# MSPM0L134X register map
Vendor: Texas Instruments; File version: This preliminary header file does not have a version number - build date: 2023-02-21 16:43:37
CPU: CM0 r0p1, little endian, MPU, no FPU, 3 interrupt priority bits
Registers are 32-bit, read-write, reset 0x0 unless marked. A register's access mark holds for its fields unless they carry their own. Offsets are from the block's base; [hi:lo] are bit positions; {n}, {i} and the like mark numbered series.

## UART0 — PERIPHERALREGION
Base 0x40108000
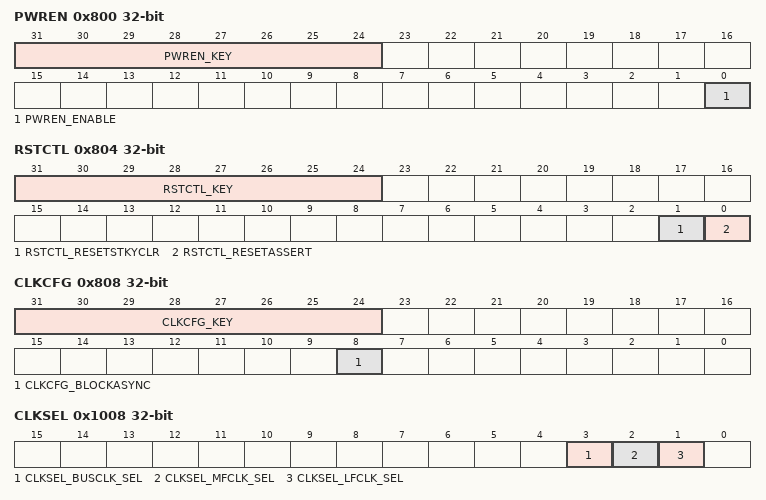
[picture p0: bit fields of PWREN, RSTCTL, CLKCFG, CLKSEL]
0x800 PWREN — Power enable
  [31:24] PWREN_KEY wo — KEY to allow Power State Change
    38=PWREN_KEY_UNLOCK_W (_TO_UNLOCK_W_)
  [0] PWREN_ENABLE — Enable the power
    0=PWREN_ENABLE_DISABLE (DISABLE); 1=PWREN_ENABLE_ENABLE (ENABLE)
0x804 RSTCTL wo — Reset Control
  [31:24] RSTCTL_KEY — Unlock key
    177=RSTCTL_KEY_UNLOCK_W (_TO_UNLOCK_W_)
  [1] RSTCTL_RESETSTKYCLR — Clear the RESETSTKY bit in the STAT register
    0=RSTCTL_RESETSTKYCLR_NOP (NOP); 1=RSTCTL_RESETSTKYCLR_CLR (CLR)
  [0] RSTCTL_RESETASSERT — Assert reset to the peripheral
    0=RSTCTL_RESETASSERT_NOP (NOP); 1=RSTCTL_RESETASSERT_ASSERT (ASSERT)
0x808 CLKCFG — Peripheral Clock Configuration Register
  [31:24] CLKCFG_KEY wo — KEY to Allow State Change -- 0xA9
    169=CLKCFG_KEY_UNLOCK (_UNLOCK_W_)
  [8] CLKCFG_BLOCKASYNC — Async Clock Request is blocked from starting SYSOSC or forcing bus clock to 32MHz
    0=CLKCFG_BLOCKASYNC_DISABLE (DISABLE); 1=CLKCFG_BLOCKASYNC_ENABLE (ENABLE)
0x814 GPRCM_STAT ro — Status Register
  [16] GPRCM_STAT_RESETSTKY — This bit indicates, if the peripheral was reset, since this bit was cleared by RESETSTKYCLR in the RSTCTL register
    0=GPRCM_STAT_RESETSTKY_NORES (NORES); 1=GPRCM_STAT_RESETSTKY_RESET (RESET)
0x1000 CLKDIV — Clock Divider
  [2:0] CLKDIV_RATIO — Selects divide ratio of module clock
    {v}=CLKDIV_RATIO_DIV_BY_{v+1} (DIV_BY_{v+1}) (v=0..7)
0x1008 CLKSEL — Clock Select for Ultra Low Power peripherals
  [3] CLKSEL_BUSCLK_SEL — Selects BUS CLK as clock source if enabled
    0=CLKSEL_BUSCLK_SEL_DISABLE (DISABLE); 1=CLKSEL_BUSCLK_SEL_ENABLE (ENABLE)
  [2] CLKSEL_MFCLK_SEL — Selects MFCLK as clock source if enabled
    0=CLKSEL_MFCLK_SEL_DISABLE (DISABLE); 1=CLKSEL_MFCLK_SEL_ENABLE (ENABLE)
  [1] CLKSEL_LFCLK_SEL — Selects LFCLK as clock source if enabled
    0=CLKSEL_LFCLK_SEL_DISABLE (DISABLE); 1=CLKSEL_LFCLK_SEL_ENABLE (ENABLE)
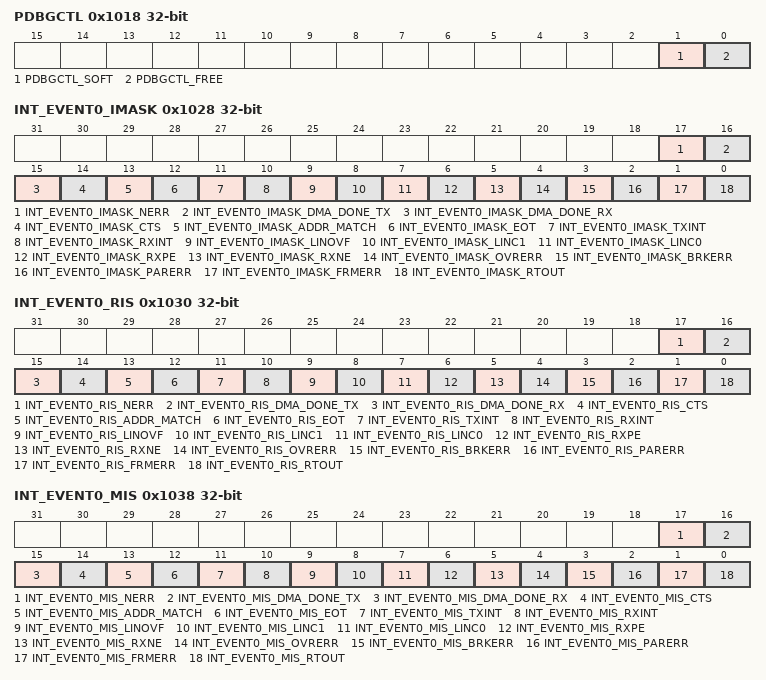
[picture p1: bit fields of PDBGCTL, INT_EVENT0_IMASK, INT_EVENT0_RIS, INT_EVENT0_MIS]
0x1018 PDBGCTL — Peripheral Debug Control
  [1] PDBGCTL_SOFT — Soft halt boundary control. This function is only available, if [FREE] is set to 'STOP'
    0=PDBGCTL_SOFT_IMMEDIATE (IMMEDIATE); 1=PDBGCTL_SOFT_DELAYED (DELAYED)
  [0] PDBGCTL_FREE — Free run control
    0=PDBGCTL_FREE_STOP (STOP); 1=PDBGCTL_FREE_RUN (RUN)
0x1020 INT_EVENT0_IIDX ro — Interrupt index
  [7:0] INT_EVENT0_IIDX_STAT — UART Module Interrupt Vector Value. This register provides the highes priority interrupt index. A read clears the corresponding interrupt flag in UARTRIS and UARTMISC. 15h-1Fh = Reserved
    0=INT_EVENT0_IIDX_STAT_NO_INTR (NO_INTR); 1=INT_EVENT0_IIDX_STAT_RTFG (RTFG); 2=INT_EVENT0_IIDX_STAT_FEFG (FEFG); 3=INT_EVENT0_IIDX_STAT_PEFG (PEFG); 4=INT_EVENT0_IIDX_STAT_BEFG (BEFG); 5=INT_EVENT0_IIDX_STAT_OEFG (OEFG); 6=INT_EVENT0_IIDX_STAT_RXNE (RXNE); 7=INT_EVENT0_IIDX_STAT_RXPE (RXPE); 8=INT_EVENT0_IIDX_STAT_LINC0 (LINC0); 9=INT_EVENT0_IIDX_STAT_LINC1 (LINC1); 10=INT_EVENT0_IIDX_STAT_LINOVF (LINOVF); 11=INT_EVENT0_IIDX_STAT_RXIFG (RXIFG); 12=INT_EVENT0_IIDX_STAT_TXIFG (TXIFG); 13=INT_EVENT0_IIDX_STAT_EOT (EOT); 14=INT_EVENT0_IIDX_STAT_MODE_9B (MODE_9B); 15=INT_EVENT0_IIDX_STAT_CTS (CTS); 16=INT_EVENT0_IIDX_STAT_DMA_DONE_RX (DMA_DONE_RX); 17=INT_EVENT0_IIDX_STAT_DMA_DONE_TX (DMA_DONE_TX); 18=INT_EVENT0_IIDX_STAT_NERR_EVT (NERR_EVT)
0x1028 INT_EVENT0_IMASK — Interrupt mask
  [17] INT_EVENT0_IMASK_NERR — Noise Error on triple voting. Asserted when the 3 samples of majority voting are not equal
    0=INT_EVENT0_IMASK_NERR_CLR (CLR); 1=INT_EVENT0_IMASK_NERR_SET (SET)
  [16] INT_EVENT0_IMASK_DMA_DONE_TX — Enable DMA Done on TX Event Channel
    0=INT_EVENT0_IMASK_DMA_DONE_TX_CLR (CLR); 1=INT_EVENT0_IMASK_DMA_DONE_TX_SET (SET)
  [15] INT_EVENT0_IMASK_DMA_DONE_RX — Enable DMA Done on RX Event Channel
    0=INT_EVENT0_IMASK_DMA_DONE_RX_CLR (CLR); 1=INT_EVENT0_IMASK_DMA_DONE_RX_SET (SET)
  [14] INT_EVENT0_IMASK_CTS — Enable UART Clear to Send Modem Interrupt. 0 = Interrupt disabled
    0=INT_EVENT0_IMASK_CTS_CLR (CLR); 1=INT_EVENT0_IMASK_CTS_SET (SET)
  [13] INT_EVENT0_IMASK_ADDR_MATCH — Enable Address Match Interrupt.
    0=INT_EVENT0_IMASK_ADDR_MATCH_CLR (CLR); 1=INT_EVENT0_IMASK_ADDR_MATCH_SET (SET)
  [12] INT_EVENT0_IMASK_EOT — Enable UART End of Transmission Interrupt Indicates that the last bit of all transmitted data and flags has left the serializer and without any further Data in the TX Fifo or Buffer.
    0=INT_EVENT0_IMASK_EOT_CLR (CLR); 1=INT_EVENT0_IMASK_EOT_SET (SET)
  [11] INT_EVENT0_IMASK_TXINT — Enable UART Transmit Interrupt.
    0=INT_EVENT0_IMASK_TXINT_CLR (CLR); 1=INT_EVENT0_IMASK_TXINT_SET (SET)
  [10] INT_EVENT0_IMASK_RXINT — Enable UART Receive Interrupt.
    0=INT_EVENT0_IMASK_RXINT_CLR (CLR); 1=INT_EVENT0_IMASK_RXINT_SET (SET)
  [9] INT_EVENT0_IMASK_LINOVF — Enable LIN Hardware Counter Overflow Interrupt.
    0=INT_EVENT0_IMASK_LINOVF_CLR (CLR); 1=INT_EVENT0_IMASK_LINOVF_SET (SET)
  [8] INT_EVENT0_IMASK_LINC1 — Enable LIN Capture 1 Interrupt.
    0=INT_EVENT0_IMASK_LINC1_CLR (CLR); 1=INT_EVENT0_IMASK_LINC1_SET (SET)
  [7] INT_EVENT0_IMASK_LINC0 — Enable LIN Capture 0 / Match Interrupt .
    0=INT_EVENT0_IMASK_LINC0_CLR (CLR); 1=INT_EVENT0_IMASK_LINC0_SET (SET)
  [6] INT_EVENT0_IMASK_RXPE — Enable Positive Edge on UARTxRXD Interrupt.
    0=INT_EVENT0_IMASK_RXPE_CLR (CLR); 1=INT_EVENT0_IMASK_RXPE_SET (SET)
  [5] INT_EVENT0_IMASK_RXNE — Enable Negative Edge on UARTxRXD Interrupt.
    0=INT_EVENT0_IMASK_RXNE_CLR (CLR); 1=INT_EVENT0_IMASK_RXNE_SET (SET)
  [4] INT_EVENT0_IMASK_OVRERR — Enable UART Receive Overrun Error Interrupt.
    0=INT_EVENT0_IMASK_OVRERR_CLR (CLR); 1=INT_EVENT0_IMASK_OVRERR_SET (SET)
  [3] INT_EVENT0_IMASK_BRKERR — Enable UART Break Error Interrupt.
    0=INT_EVENT0_IMASK_BRKERR_CLR (CLR); 1=INT_EVENT0_IMASK_BRKERR_SET (SET)
  [2] INT_EVENT0_IMASK_PARERR — Enable UART Parity Error Interrupt.
    0=INT_EVENT0_IMASK_PARERR_CLR (CLR); 1=INT_EVENT0_IMASK_PARERR_SET (SET)
  [1] INT_EVENT0_IMASK_FRMERR — Enable UART Framing Error Interrupt.
    0=INT_EVENT0_IMASK_FRMERR_CLR (CLR); 1=INT_EVENT0_IMASK_FRMERR_SET (SET)
  [0] INT_EVENT0_IMASK_RTOUT — Enable UARTOUT Receive Time-Out Interrupt.
    0=INT_EVENT0_IMASK_RTOUT_CLR (CLR); 1=INT_EVENT0_IMASK_RTOUT_SET (SET)
0x1030 INT_EVENT0_RIS ro — Raw interrupt status
  [17] INT_EVENT0_RIS_NERR — Noise Error on triple voting. Asserted when the 3 samples of majority voting are not equal
    0=INT_EVENT0_RIS_NERR_CLR (CLR); 1=INT_EVENT0_RIS_NERR_SET (SET)
  [16] INT_EVENT0_RIS_DMA_DONE_TX — DMA Done on TX Event Channel
    0=INT_EVENT0_RIS_DMA_DONE_TX_CLR (CLR); 1=INT_EVENT0_RIS_DMA_DONE_TX_SET (SET)
  [15] INT_EVENT0_RIS_DMA_DONE_RX — DMA Done on RX Event Channel
    0=INT_EVENT0_RIS_DMA_DONE_RX_CLR (CLR); 1=INT_EVENT0_RIS_DMA_DONE_RX_SET (SET)
  [14] INT_EVENT0_RIS_CTS — UART Clear to Send Modem Interrupt. 0 = Interrupt disabled
    0=INT_EVENT0_RIS_CTS_CLR (CLR); 1=INT_EVENT0_RIS_CTS_SET (SET)
  [13] INT_EVENT0_RIS_ADDR_MATCH — Address Match Interrupt.
    0=INT_EVENT0_RIS_ADDR_MATCH_CLR (CLR); 1=INT_EVENT0_RIS_ADDR_MATCH_SET (SET)
  [12] INT_EVENT0_RIS_EOT — UART End of Transmission Interrupt Indicates that the last bit of all transmitted data and flags has left the serializer and without any further Data in the TX Fifo or Buffer.
    0=INT_EVENT0_RIS_EOT_CLR (CLR); 1=INT_EVENT0_RIS_EOT_SET (SET)
  [11] INT_EVENT0_RIS_TXINT — UART Transmit Interrupt.
    0=INT_EVENT0_RIS_TXINT_CLR (CLR); 1=INT_EVENT0_RIS_TXINT_SET (SET)
  [10] INT_EVENT0_RIS_RXINT — UART Receive Interrupt.
    0=INT_EVENT0_RIS_RXINT_CLR (CLR); 1=INT_EVENT0_RIS_RXINT_SET (SET)
  [9] INT_EVENT0_RIS_LINOVF — LIN Hardware Counter Overflow Interrupt.
    0=INT_EVENT0_RIS_LINOVF_CLR (CLR); 1=INT_EVENT0_RIS_LINOVF_SET (SET)
  [8] INT_EVENT0_RIS_LINC1 — LIN Capture 1 Interrupt.
    0=INT_EVENT0_RIS_LINC1_CLR (CLR); 1=INT_EVENT0_RIS_LINC1_SET (SET)
  [7] INT_EVENT0_RIS_LINC0 — LIN Capture 0 / Match Interrupt .
    0=INT_EVENT0_RIS_LINC0_CLR (CLR); 1=INT_EVENT0_RIS_LINC0_SET (SET)
  [6] INT_EVENT0_RIS_RXPE — Positive Edge on UARTxRXD Interrupt.
    0=INT_EVENT0_RIS_RXPE_CLR (CLR); 1=INT_EVENT0_RIS_RXPE_SET (SET)
  [5] INT_EVENT0_RIS_RXNE — Negative Edge on UARTxRXD Interrupt.
    0=INT_EVENT0_RIS_RXNE_CLR (CLR); 1=INT_EVENT0_RIS_RXNE_SET (SET)
  [4] INT_EVENT0_RIS_OVRERR — UART Receive Overrun Error Interrupt.
    0=INT_EVENT0_RIS_OVRERR_CLR (CLR); 1=INT_EVENT0_RIS_OVRERR_SET (SET)
  [3] INT_EVENT0_RIS_BRKERR — UART Break Error Interrupt.
    0=INT_EVENT0_RIS_BRKERR_CLR (CLR); 1=INT_EVENT0_RIS_BRKERR_SET (SET)
  [2] INT_EVENT0_RIS_PARERR — UART Parity Error Interrupt.
    0=INT_EVENT0_RIS_PARERR_CLR (CLR); 1=INT_EVENT0_RIS_PARERR_SET (SET)
  [1] INT_EVENT0_RIS_FRMERR — UART Framing Error Interrupt.
    0=INT_EVENT0_RIS_FRMERR_CLR (CLR); 1=INT_EVENT0_RIS_FRMERR_SET (SET)
  [0] INT_EVENT0_RIS_RTOUT — UARTOUT Receive Time-Out Interrupt.
    0=INT_EVENT0_RIS_RTOUT_CLR (CLR); 1=INT_EVENT0_RIS_RTOUT_SET (SET)
0x1038 INT_EVENT0_MIS ro — Masked interrupt status
  [17] INT_EVENT0_MIS_NERR — Noise Error on triple voting. Asserted when the 3 samples of majority voting are not equal
    0=INT_EVENT0_MIS_NERR_CLR (CLR); 1=INT_EVENT0_MIS_NERR_SET (SET)
  [16] INT_EVENT0_MIS_DMA_DONE_TX — Masked DMA Done on TX Event Channel
    0=INT_EVENT0_MIS_DMA_DONE_TX_CLR (CLR); 1=INT_EVENT0_MIS_DMA_DONE_TX_SET (SET)
  [15] INT_EVENT0_MIS_DMA_DONE_RX — Masked DMA Done on RX Event Channel
    0=INT_EVENT0_MIS_DMA_DONE_RX_CLR (CLR); 1=INT_EVENT0_MIS_DMA_DONE_RX_SET (SET)
  [14] INT_EVENT0_MIS_CTS — Masked UART Clear to Send Modem Interrupt. 0 = Interrupt disabled
    0=INT_EVENT0_MIS_CTS_CLR (CLR); 1=INT_EVENT0_MIS_CTS_SET (SET)
  [13] INT_EVENT0_MIS_ADDR_MATCH — Masked Address Match Interrupt.
    0=INT_EVENT0_MIS_ADDR_MATCH_CLR (CLR); 1=INT_EVENT0_MIS_ADDR_MATCH_SET (SET)
  [12] INT_EVENT0_MIS_EOT — UART End of Transmission Interrupt Indicates that the last bit of all transmitted data and flags has left the serializer and without any further Data in the TX Fifo or Buffer.
    0=INT_EVENT0_MIS_EOT_CLR (CLR); 1=INT_EVENT0_MIS_EOT_SET (SET)
  [11] INT_EVENT0_MIS_TXINT — Masked UART Transmit Interrupt.
    0=INT_EVENT0_MIS_TXINT_CLR (CLR); 1=INT_EVENT0_MIS_TXINT_SET (SET)
  [10] INT_EVENT0_MIS_RXINT — Masked UART Receive Interrupt.
    0=INT_EVENT0_MIS_RXINT_CLR (CLR); 1=INT_EVENT0_MIS_RXINT_SET (SET)
  [9] INT_EVENT0_MIS_LINOVF — Masked LIN Hardware Counter Overflow Interrupt.
    0=INT_EVENT0_MIS_LINOVF_CLR (CLR); 1=INT_EVENT0_MIS_LINOVF_SET (SET)
  [8] INT_EVENT0_MIS_LINC1 — Masked LIN Capture 1 Interrupt.
    0=INT_EVENT0_MIS_LINC1_CLR (CLR); 1=INT_EVENT0_MIS_LINC1_SET (SET)
  [7] INT_EVENT0_MIS_LINC0 — Masked LIN Capture 0 / Match Interrupt .
    0=INT_EVENT0_MIS_LINC0_CLR (CLR); 1=INT_EVENT0_MIS_LINC0_SET (SET)
  [6] INT_EVENT0_MIS_RXPE — Masked Positive Edge on UARTxRXD Interrupt.
    0=INT_EVENT0_MIS_RXPE_CLR (CLR); 1=INT_EVENT0_MIS_RXPE_SET (SET)
  [5] INT_EVENT0_MIS_RXNE — Masked Negative Edge on UARTxRXD Interrupt.
    0=INT_EVENT0_MIS_RXNE_CLR (CLR); 1=INT_EVENT0_MIS_RXNE_SET (SET)
  [4] INT_EVENT0_MIS_OVRERR — Masked UART Receive Overrun Error Interrupt.
    0=INT_EVENT0_MIS_OVRERR_CLR (CLR); 1=INT_EVENT0_MIS_OVRERR_SET (SET)
  [3] INT_EVENT0_MIS_BRKERR — Masked UART Break Error Interrupt.
    0=INT_EVENT0_MIS_BRKERR_CLR (CLR); 1=INT_EVENT0_MIS_BRKERR_SET (SET)
  [2] INT_EVENT0_MIS_PARERR — Masked UART Parity Error Interrupt.
    0=INT_EVENT0_MIS_PARERR_CLR (CLR); 1=INT_EVENT0_MIS_PARERR_SET (SET)
  [1] INT_EVENT0_MIS_FRMERR — Masked UART Framing Error Interrupt.
    0=INT_EVENT0_MIS_FRMERR_CLR (CLR); 1=INT_EVENT0_MIS_FRMERR_SET (SET)
  [0] INT_EVENT0_MIS_RTOUT — Masked UARTOUT Receive Time-Out Interrupt.
    0=INT_EVENT0_MIS_RTOUT_CLR (CLR); 1=INT_EVENT0_MIS_RTOUT_SET (SET)
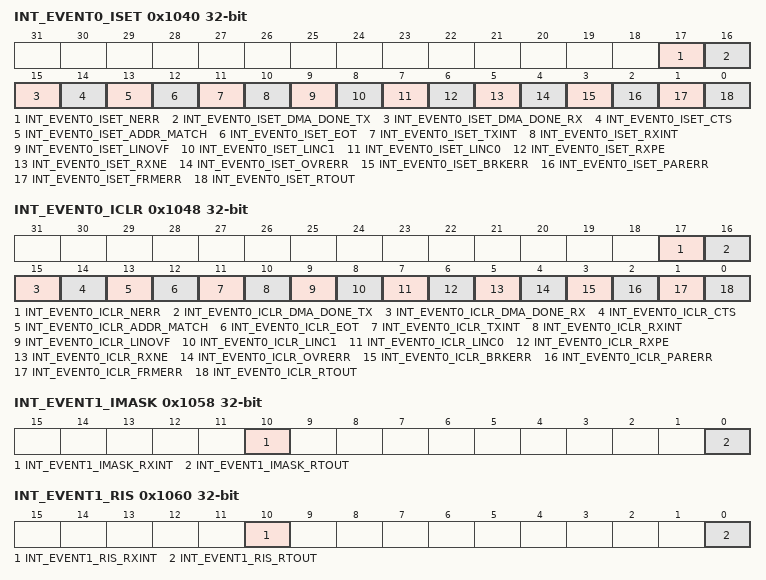
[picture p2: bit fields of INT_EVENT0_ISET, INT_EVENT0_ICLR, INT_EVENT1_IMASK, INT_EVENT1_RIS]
0x1040 INT_EVENT0_ISET wo — Interrupt set
  [17] INT_EVENT0_ISET_NERR — Noise Error on triple voting. Asserted when the 3 samples of majority voting are not equal
    0=INT_EVENT0_ISET_NERR_NO_EFFECT (NO_EFFECT); 1=INT_EVENT0_ISET_NERR_SET (SET)
  [16] INT_EVENT0_ISET_DMA_DONE_TX — Set DMA Done on TX Event Channel
    0=INT_EVENT0_ISET_DMA_DONE_TX_NO_EFFECT (NO_EFFECT); 1=INT_EVENT0_ISET_DMA_DONE_TX_SET (SET)
  [15] INT_EVENT0_ISET_DMA_DONE_RX — Set DMA Done on RX Event Channel
    0=INT_EVENT0_ISET_DMA_DONE_RX_NO_EFFECT (NO_EFFECT); 1=INT_EVENT0_ISET_DMA_DONE_RX_SET (SET)
  [14] INT_EVENT0_ISET_CTS — Set UART Clear to Send Modem Interrupt. 0 = Interrupt disabled
    0=INT_EVENT0_ISET_CTS_NO_EFFECT (NO_EFFECT); 1=INT_EVENT0_ISET_CTS_SET (SET)
  [13] INT_EVENT0_ISET_ADDR_MATCH — Set Address Match Interrupt.
    0=INT_EVENT0_ISET_ADDR_MATCH_NO_EFFECT (NO_EFFECT); 1=INT_EVENT0_ISET_ADDR_MATCH_SET (SET)
  [12] INT_EVENT0_ISET_EOT — Set UART End of Transmission Interrupt Indicates that the last bit of all transmitted data and flags has left the serializer and without any further Data in the TX Fifo or Buffer.
    0=INT_EVENT0_ISET_EOT_NO_EFFECT (NO_EFFECT); 1=INT_EVENT0_ISET_EOT_SET (SET)
  [11] INT_EVENT0_ISET_TXINT — Set UART Transmit Interrupt.
    0=INT_EVENT0_ISET_TXINT_NO_EFFECT (NO_EFFECT); 1=INT_EVENT0_ISET_TXINT_SET (SET)
  [10] INT_EVENT0_ISET_RXINT — Set UART Receive Interrupt.
    0=INT_EVENT0_ISET_RXINT_NO_EFFECT (NO_EFFECT); 1=INT_EVENT0_ISET_RXINT_SET (SET)
  [9] INT_EVENT0_ISET_LINOVF — Set LIN Hardware Counter Overflow Interrupt.
    0=INT_EVENT0_ISET_LINOVF_NO_EFFECT (NO_EFFECT); 1=INT_EVENT0_ISET_LINOVF_SET (SET)
  [8] INT_EVENT0_ISET_LINC1 — Set LIN Capture 1 Interrupt.
    0=INT_EVENT0_ISET_LINC1_NO_EFFECT (NO_EFFECT); 1=INT_EVENT0_ISET_LINC1_SET (SET)
  [7] INT_EVENT0_ISET_LINC0 — Set LIN Capture 0 / Match Interrupt .
    0=INT_EVENT0_ISET_LINC0_NO_EFFECT (NO_EFFECT); 1=INT_EVENT0_ISET_LINC0_SET (SET)
  [6] INT_EVENT0_ISET_RXPE — Set Positive Edge on UARTxRXD Interrupt.
    0=INT_EVENT0_ISET_RXPE_NO_EFFECT (NO_EFFECT); 1=INT_EVENT0_ISET_RXPE_SET (SET)
  [5] INT_EVENT0_ISET_RXNE — Set Negative Edge on UARTxRXD Interrupt.
    0=INT_EVENT0_ISET_RXNE_NO_EFFECT (NO_EFFECT); 1=INT_EVENT0_ISET_RXNE_SET (SET)
  [4] INT_EVENT0_ISET_OVRERR — Set UART Receive Overrun Error Interrupt.
    0=INT_EVENT0_ISET_OVRERR_NO_EFFECT (NO_EFFECT); 1=INT_EVENT0_ISET_OVRERR_SET (SET)
  [3] INT_EVENT0_ISET_BRKERR — Set UART Break Error Interrupt.
    0=INT_EVENT0_ISET_BRKERR_NO_EFFECT (NO_EFFECT); 1=INT_EVENT0_ISET_BRKERR_SET (SET)
  [2] INT_EVENT0_ISET_PARERR — Set UART Parity Error Interrupt.
    0=INT_EVENT0_ISET_PARERR_NO_EFFECT (NO_EFFECT); 1=INT_EVENT0_ISET_PARERR_SET (SET)
  [1] INT_EVENT0_ISET_FRMERR — Set UART Framing Error Interrupt.
    0=INT_EVENT0_ISET_FRMERR_NO_EFFECT (NO_EFFECT); 1=INT_EVENT0_ISET_FRMERR_SET (SET)
  [0] INT_EVENT0_ISET_RTOUT — Set UARTOUT Receive Time-Out Interrupt.
    0=INT_EVENT0_ISET_RTOUT_NO_EFFECT (NO_EFFECT); 1=INT_EVENT0_ISET_RTOUT_SET (SET)
0x1048 INT_EVENT0_ICLR wo — Interrupt clear
  [17] INT_EVENT0_ICLR_NERR — Noise Error on triple voting. Asserted when the 3 samples of majority voting are not equal
    0=INT_EVENT0_ICLR_NERR_NO_EFFECT (NO_EFFECT); 1=INT_EVENT0_ICLR_NERR_CLR (CLR)
  [16] INT_EVENT0_ICLR_DMA_DONE_TX — Clear DMA Done on TX Event Channel
    0=INT_EVENT0_ICLR_DMA_DONE_TX_NO_EFFECT (NO_EFFECT); 1=INT_EVENT0_ICLR_DMA_DONE_TX_CLR (CLR)
  [15] INT_EVENT0_ICLR_DMA_DONE_RX — Clear DMA Done on RX Event Channel
    0=INT_EVENT0_ICLR_DMA_DONE_RX_NO_EFFECT (NO_EFFECT); 1=INT_EVENT0_ICLR_DMA_DONE_RX_CLR (CLR)
  [14] INT_EVENT0_ICLR_CTS — Clear UART Clear to Send Modem Interrupt. 0 = Interrupt disabled
    0=INT_EVENT0_ICLR_CTS_NO_EFFECT (NO_EFFECT); 1=INT_EVENT0_ICLR_CTS_CLR (CLR)
  [13] INT_EVENT0_ICLR_ADDR_MATCH — Clear Address Match Interrupt.
    0=INT_EVENT0_ICLR_ADDR_MATCH_NO_EFFECT (NO_EFFECT); 1=INT_EVENT0_ICLR_ADDR_MATCH_CLR (CLR)
  [12] INT_EVENT0_ICLR_EOT — Clear UART End of Transmission Interrupt Indicates that the last bit of all transmitted data and flags has left the serializer and without any further Data in the TX Fifo or Buffer.
    0=INT_EVENT0_ICLR_EOT_NO_EFFECT (NO_EFFECT); 1=INT_EVENT0_ICLR_EOT_CLR (CLR)
  [11] INT_EVENT0_ICLR_TXINT — Clear UART Transmit Interrupt.
    0=INT_EVENT0_ICLR_TXINT_NO_EFFECT (NO_EFFECT); 1=INT_EVENT0_ICLR_TXINT_CLR (CLR)
  [10] INT_EVENT0_ICLR_RXINT — Clear UART Receive Interrupt.
    0=INT_EVENT0_ICLR_RXINT_NO_EFFECT (NO_EFFECT); 1=INT_EVENT0_ICLR_RXINT_CLR (CLR)
  [9] INT_EVENT0_ICLR_LINOVF — Clear LIN Hardware Counter Overflow Interrupt.
    0=INT_EVENT0_ICLR_LINOVF_NO_EFFECT (NO_EFFECT); 1=INT_EVENT0_ICLR_LINOVF_CLR (CLR)
  [8] INT_EVENT0_ICLR_LINC1 — Clear LIN Capture 1 Interrupt.
    0=INT_EVENT0_ICLR_LINC1_NO_EFFECT (NO_EFFECT); 1=INT_EVENT0_ICLR_LINC1_CLR (CLR)
  [7] INT_EVENT0_ICLR_LINC0 — Clear LIN Capture 0 / Match Interrupt .
    0=INT_EVENT0_ICLR_LINC0_NO_EFFECT (NO_EFFECT); 1=INT_EVENT0_ICLR_LINC0_CLR (CLR)
  [6] INT_EVENT0_ICLR_RXPE — Clear Positive Edge on UARTxRXD Interrupt.
    0=INT_EVENT0_ICLR_RXPE_NO_EFFECT (NO_EFFECT); 1=INT_EVENT0_ICLR_RXPE_CLR (CLR)
  [5] INT_EVENT0_ICLR_RXNE — Clear Negative Edge on UARTxRXD Interrupt.
    0=INT_EVENT0_ICLR_RXNE_NO_EFFECT (NO_EFFECT); 1=INT_EVENT0_ICLR_RXNE_CLR (CLR)
  [4] INT_EVENT0_ICLR_OVRERR — Clear UART Receive Overrun Error Interrupt.
    0=INT_EVENT0_ICLR_OVRERR_NO_EFFECT (NO_EFFECT); 1=INT_EVENT0_ICLR_OVRERR_CLR (CLR)
  [3] INT_EVENT0_ICLR_BRKERR — Clear UART Break Error Interrupt.
    0=INT_EVENT0_ICLR_BRKERR_NO_EFFECT (NO_EFFECT); 1=INT_EVENT0_ICLR_BRKERR_CLR (CLR)
  [2] INT_EVENT0_ICLR_PARERR — Clear UART Parity Error Interrupt.
    0=INT_EVENT0_ICLR_PARERR_NO_EFFECT (NO_EFFECT); 1=INT_EVENT0_ICLR_PARERR_CLR (CLR)
  [1] INT_EVENT0_ICLR_FRMERR — Clear UART Framing Error Interrupt.
    0=INT_EVENT0_ICLR_FRMERR_NO_EFFECT (NO_EFFECT); 1=INT_EVENT0_ICLR_FRMERR_CLR (CLR)
  [0] INT_EVENT0_ICLR_RTOUT — Clear UARTOUT Receive Time-Out Interrupt.
    0=INT_EVENT0_ICLR_RTOUT_NO_EFFECT (NO_EFFECT); 1=INT_EVENT0_ICLR_RTOUT_CLR (CLR)
0x1050 INT_EVENT1_IIDX ro — Interrupt index
  [7:0] INT_EVENT1_IIDX_STAT — UART Module Interrupt Vector Value. This register provides the highes priority interrupt index. A read clears the corresponding interrupt flag in UARTRIS and UARTMISC. 15h-1Fh = Reserved
    0=INT_EVENT1_IIDX_STAT_NO_INTR (NO_INTR); 1=INT_EVENT1_IIDX_STAT_RTFG (RTFG); 11=INT_EVENT1_IIDX_STAT_RXIFG (RXIFG)
0x1058 INT_EVENT1_IMASK — Interrupt mask
  [10] INT_EVENT1_IMASK_RXINT — Enable UART Receive Interrupt.
    0=INT_EVENT1_IMASK_RXINT_CLR (CLR); 1=INT_EVENT1_IMASK_RXINT_SET (SET)
  [0] INT_EVENT1_IMASK_RTOUT — Enable UARTOUT Receive Time-Out Interrupt.
    0=INT_EVENT1_IMASK_RTOUT_CLR (CLR); 1=INT_EVENT1_IMASK_RTOUT_SET (SET)
0x1060 INT_EVENT1_RIS ro — Raw interrupt status
  [10] INT_EVENT1_RIS_RXINT — UART Receive Interrupt.
    0=INT_EVENT1_RIS_RXINT_CLR (CLR); 1=INT_EVENT1_RIS_RXINT_SET (SET)
  [0] INT_EVENT1_RIS_RTOUT — UARTOUT Receive Time-Out Interrupt.
    0=INT_EVENT1_RIS_RTOUT_CLR (CLR); 1=INT_EVENT1_RIS_RTOUT_SET (SET)
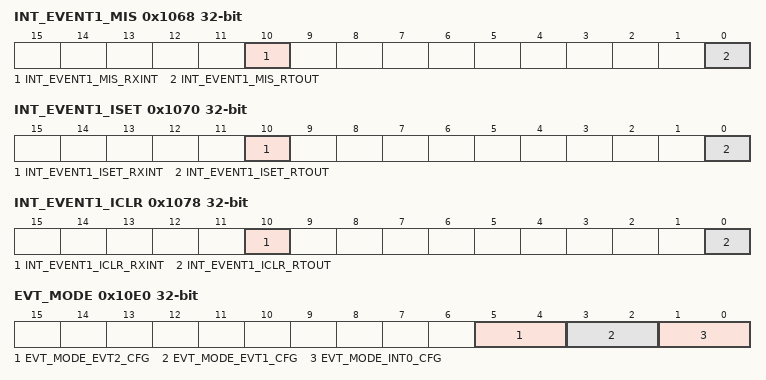
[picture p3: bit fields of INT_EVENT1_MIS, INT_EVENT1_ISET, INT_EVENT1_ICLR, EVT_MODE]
0x1068 INT_EVENT1_MIS ro — Masked interrupt status
  [10] INT_EVENT1_MIS_RXINT — Masked UART Receive Interrupt.
    0=INT_EVENT1_MIS_RXINT_CLR (CLR); 1=INT_EVENT1_MIS_RXINT_SET (SET)
  [0] INT_EVENT1_MIS_RTOUT — Masked UARTOUT Receive Time-Out Interrupt.
    0=INT_EVENT1_MIS_RTOUT_CLR (CLR); 1=INT_EVENT1_MIS_RTOUT_SET (SET)
0x1070 INT_EVENT1_ISET wo — Interrupt set
  [10] INT_EVENT1_ISET_RXINT — Set UART Receive Interrupt.
    0=INT_EVENT1_ISET_RXINT_NO_EFFECT (NO_EFFECT); 1=INT_EVENT1_ISET_RXINT_SET (SET)
  [0] INT_EVENT1_ISET_RTOUT — Set UARTOUT Receive Time-Out Interrupt.
    0=INT_EVENT1_ISET_RTOUT_NO_EFFECT (NO_EFFECT); 1=INT_EVENT1_ISET_RTOUT_SET (SET)
0x1078 INT_EVENT1_ICLR wo — Interrupt clear
  [10] INT_EVENT1_ICLR_RXINT — Clear UART Receive Interrupt.
    0=INT_EVENT1_ICLR_RXINT_NO_EFFECT (NO_EFFECT); 1=INT_EVENT1_ICLR_RXINT_CLR (CLR)
  [0] INT_EVENT1_ICLR_RTOUT — Clear UARTOUT Receive Time-Out Interrupt.
    0=INT_EVENT1_ICLR_RTOUT_NO_EFFECT (NO_EFFECT); 1=INT_EVENT1_ICLR_RTOUT_CLR (CLR)
0x1080 INT_EVENT2_IIDX ro — Interrupt index
  [7:0] INT_EVENT2_IIDX_STAT — UART Module Interrupt Vector Value. This register provides the highes priority interrupt index. A read clears the corresponding interrupt flag in UARTRIS and UARTMISC. 15h-1Fh = Reserved
    0=INT_EVENT2_IIDX_STAT_NO_INTR (NO_INTR); 12=INT_EVENT2_IIDX_STAT_TXIFG (TXIFG)
0x1088 INT_EVENT2_IMASK — Interrupt mask
  [11] INT_EVENT2_IMASK_TXINT — Enable UART Transmit Interrupt.
    0=INT_EVENT2_IMASK_TXINT_CLR (CLR); 1=INT_EVENT2_IMASK_TXINT_SET (SET)
0x1090 INT_EVENT2_RIS ro — Raw interrupt status
  [11] INT_EVENT2_RIS_TXINT — UART Transmit Interrupt.
    0=INT_EVENT2_RIS_TXINT_CLR (CLR); 1=INT_EVENT2_RIS_TXINT_SET (SET)
0x1098 INT_EVENT2_MIS ro — Masked interrupt status
  [11] INT_EVENT2_MIS_TXINT — Masked UART Transmit Interrupt.
    0=INT_EVENT2_MIS_TXINT_CLR (CLR); 1=INT_EVENT2_MIS_TXINT_SET (SET)
0x10A0 INT_EVENT2_ISET wo — Interrupt set
  [11] INT_EVENT2_ISET_TXINT — Set UART Transmit Interrupt.
    0=INT_EVENT2_ISET_TXINT_NO_EFFECT (NO_EFFECT); 1=INT_EVENT2_ISET_TXINT_SET (SET)
0x10A8 INT_EVENT2_ICLR wo — Interrupt clear
  [11] INT_EVENT2_ICLR_TXINT — Clear UART Transmit Interrupt.
    0=INT_EVENT2_ICLR_TXINT_NO_EFFECT (NO_EFFECT); 1=INT_EVENT2_ICLR_TXINT_CLR (CLR)
0x10E0 EVT_MODE — Event Mode
  [5:4] EVT_MODE_EVT2_CFG ro — Event line mode select for event corresponding to [IPSTANDARD.INT_EVENT2]
    0=EVT_MODE_EVT2_CFG_DISABLE (DISABLE); 1=EVT_MODE_EVT2_CFG_SOFTWARE (SOFTWARE); 2=EVT_MODE_EVT2_CFG_HARDWARE (HARDWARE)
  [3:2] EVT_MODE_EVT1_CFG ro — Event line mode select for event corresponding to [IPSTANDARD.INT_EVENT1]
    0=EVT_MODE_EVT1_CFG_DISABLE (DISABLE); 1=EVT_MODE_EVT1_CFG_SOFTWARE (SOFTWARE); 2=EVT_MODE_EVT1_CFG_HARDWARE (HARDWARE)
  [1:0] EVT_MODE_INT0_CFG ro — Event line mode select for event corresponding to [IPSTANDARD.INT_EVENT0]
    0=EVT_MODE_INT0_CFG_DISABLE (DISABLE); 1=EVT_MODE_INT0_CFG_SOFTWARE (SOFTWARE); 2=EVT_MODE_INT0_CFG_HARDWARE (HARDWARE)
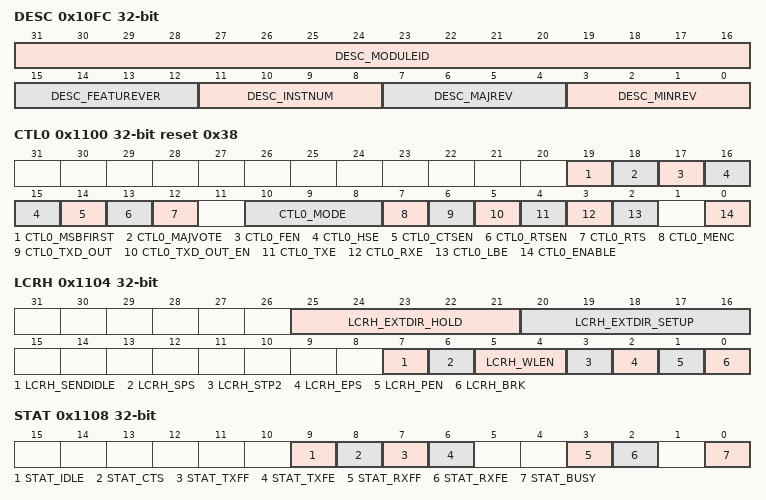
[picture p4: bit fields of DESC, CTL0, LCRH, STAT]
0x10FC DESC ro — Module Description
  [31:16] DESC_MODULEID — Module identification contains a unique peripheral identification number. The assignments are maintained in a central database for all of the platform modules to ensure uniqueness.
  [15:12] DESC_FEATUREVER — Feature Set for the module *instance*
  [11:8] DESC_INSTNUM — Instance Number within the device. This will be a parameter to the RTL for modules that can have multiple instances
  [7:4] DESC_MAJREV — Major rev of the IP
  [3:0] DESC_MINREV — Minor rev of the IP
0x1100 CTL0 reset 0x38 — UART Control Register 0
  [19] CTL0_MSBFIRST — Most Significant Bit First This bit has effect both on the way protocol byte is transmitted and received. Notes: User needs to match the protocol to the correct value of this bit to send MSb or LSb first. The hardware engine will send the byte entirely based on this bit.
    0=CTL0_MSBFIRST_DISABLE (DISABLE); 1=CTL0_MSBFIRST_ENABLE (ENABLE)
  [18] CTL0_MAJVOTE — When enabled with oversmapling of 16, samples samples 7, 8, and 9 are majority voted to decide the sampled bit value. The value correspond to al least 2 of the 3 samples is considered to be the received value. In case the 3 values do not match, RIS.NERR bit is set along with RDR.NERR When enabled with oversmapling of 8, samples samples 3, 4, and 5 are majority voted to decide the sampled bit value. The value correspond to al least 2 of the 3 samples is considered to be the received value. In case the 3 values donot match, RIS.NERR bit is set along with RDR.NERR When disabled, only a single sample of received bit is taken.
    0=CTL0_MAJVOTE_DISABLE (DISABLE); 1=CTL0_MAJVOTE_ENABLE (ENABLE)
  [17] CTL0_FEN — UART Enable FIFOs
    0=CTL0_FEN_DISABLE (DISABLE); 1=CTL0_FEN_ENABLE (ENABLE)
  [16:15] CTL0_HSE — High-Speed Bit Oversampling Enable #b#NOTE:#/b# The bit oversampling influences the UART baud-rate configuration (see and ). The state of this bit has no effect on clock generation in ISO7816 smart card mode (the SMART bit is set).
    0=CTL0_HSE_OVS16 (OVS16); 1=CTL0_HSE_OVS8 (OVS8); 2=CTL0_HSE_OVS3 (OVS3)
  [14] CTL0_CTSEN — Enable Clear To Send
    0=CTL0_CTSEN_DISABLE (DISABLE); 1=CTL0_CTSEN_ENABLE (ENABLE)
  [13] CTL0_RTSEN — Enable hardware controlled Request to Send
    0=CTL0_RTSEN_DISABLE (DISABLE); 1=CTL0_RTSEN_ENABLE (ENABLE)
  [12] CTL0_RTS — Request to Send If RTSEN is set the RTS output signals is controlled by the hardware logic using the FIFO fill level or TXDATA buffer. If RTSEN is cleared the RTS output is controlled by the RTS bit. The bit is the complement of the UART request to send, RTS modem status output.
    0=CTL0_RTS_CLR (CLR); 1=CTL0_RTS_SET (SET)
  [10:8] CTL0_MODE — Set the communication mode and protocol used. (Not defined settings uses the default setting: 0)
    0=CTL0_MODE_UART (UART); 1=CTL0_MODE_RS485 (RS485); 2=CTL0_MODE_IDLELINE (IDLELINE); 3=CTL0_MODE_ADDR9BIT (ADDR9BIT); 4=CTL0_MODE_SMART (SMART); 5=CTL0_MODE_DALI (DALI)
  [7] CTL0_MENC — Manchester Encode enable
    0=CTL0_MENC_DISABLE (DISABLE); 1=CTL0_MENC_ENABLE (ENABLE)
  [6] CTL0_TXD_OUT — TXD Pin Control Controls the TXD pin when TXD_OUT_EN = 1 and TXE = 0.
    0=CTL0_TXD_OUT_LOW (LOW); 1=CTL0_TXD_OUT_HIGH (HIGH)
  [5] CTL0_TXD_OUT_EN — TXD Pin Control Enable. When the transmit section of the UART is disabled (TXE = 0), the TXD pin can be controlled by the TXD_OUT bit. 1 = UARTxTXD pin can be controlled by TXD_OUT, if TXE = 0
    0=CTL0_TXD_OUT_EN_DISABLE (DISABLE); 1=CTL0_TXD_OUT_EN_ENABLE (ENABLE)
  [4] CTL0_TXE — UART Transmit Enable If the UART is disabled in the middle of a transmission, it completes the current character before stopping. #b#NOTE:#/b# To enable transmission, the UARTEN bit must be set.
    0=CTL0_TXE_DISABLE (DISABLE); 1=CTL0_TXE_ENABLE (ENABLE)
  [3] CTL0_RXE — UART Receive Enable If the UART is disabled in the middle of a receive, it completes the current character before stopping. #b#NOTE:#/b# To enable reception, the UARTEN bit must be set.
    0=CTL0_RXE_DISABLE (DISABLE); 1=CTL0_RXE_ENABLE (ENABLE)
  [2] CTL0_LBE — UART Loop Back Enable
    0=CTL0_LBE_DISABLE (DISABLE); 1=CTL0_LBE_ENABLE (ENABLE)
  [0] CTL0_ENABLE — UART Module Enable. If the UART is disabled in the middle of transmission or reception, it completes the current character before stopping. If the ENABLE bit is not set, all registers can still be accessed and updated. It is recommended to setup and change the UART operation mode with having the ENABLE bit cleared to avoid unpredictable behavior during the setup or update. If disabled the UART module will not send or receive any data and the logic is held in reset state.
    0=CTL0_ENABLE_DISABLE (DISABLE); 1=CTL0_ENABLE_ENABLE (ENABLE)
0x1104 LCRH — UART Line Control Register
  [25:21] LCRH_EXTDIR_HOLD — Defines the number of UARTclk ticks the signal to control the external driver for the RS485 will be reset after the beginning of the stop bit. (If 2 STOP bits are enabled the beginning of the 2nd STOP bit.)
  [20:16] LCRH_EXTDIR_SETUP — Defines the number of UARTclk ticks the signal to control the external driver for the RS485 will be set before the START bit is send
  [7] LCRH_SENDIDLE — UART send IDLE pattern. When this bit is set an SENDIDLE period of 11 bit times will be sent on the TX line. The bit is cleared by hardware afterwards.
    0=LCRH_SENDIDLE_DISABLE (DISABLE); 1=LCRH_SENDIDLE_ENABLE (ENABLE)
  [6] LCRH_SPS — UART Stick Parity Select The Stick Parity Select (SPS) bit is used to set either a permanent '1' or a permanent '0' as parity when transmitting or receiving data. Its purpose is to typically indicate the first byte of a package or to mark an address byte, for example in a multi-drop RS-485 network. 0h = Stick parity is disabled 1h = Stick parity is enabled. When bits PEN, EPS, and SPS of UARTLCRH are set, the parity bit is transmitted and checked as a 0. When bits PEN and SPS are set and EPS is cleared, the parity bit is transmitted and checked as a 1.
    0=LCRH_SPS_DISABLE (DISABLE); 1=LCRH_SPS_ENABLE (ENABLE)
  [5:4] LCRH_WLEN — UART Word Length The bits indicate the number of data bits transmitted or received in a frame as follows:
    {v}=LCRH_WLEN_DATABIT{v+5} (DATABIT{v+5}) (v=0..3)
  [3] LCRH_STP2 — UART Two Stop Bits Select When in 7816 smart card mode (the SMART bit is set in the UARTCTL register), the number of stop bits is forced to 2.
    0=LCRH_STP2_DISABLE (DISABLE); 1=LCRH_STP2_ENABLE (ENABLE)
  [2] LCRH_EPS — UART Even Parity Select This bit has no effect when parity is disabled by the PEN bit. For 9-Bit UART Mode transmissions, this bit controls the address byte and data byte indication (9th bit). 0 = The transferred byte is a data byte 1 = The transferred byte is an address byte
    0=LCRH_EPS_ODD (ODD); 1=LCRH_EPS_EVEN (EVEN)
  [1] LCRH_PEN — UART Parity Enable
    0=LCRH_PEN_DISABLE (DISABLE); 1=LCRH_PEN_ENABLE (ENABLE)
  [0] LCRH_BRK — UART Send Break (for LIN Protocol)
    0=LCRH_BRK_DISABLE (DISABLE); 1=LCRH_BRK_ENABLE (ENABLE)
0x1108 STAT ro — UART Status Register
  [9] STAT_IDLE — IDLE mode has been detected in Idleline-Mulitprocessor-Mode. The IDLE bit is used as an address tag for each block of characters. In idle-line multiprocessor format, this bit is set when a received character is an address.
    0=STAT_IDLE_CLEARED (CLEARED); 1=STAT_IDLE_SET (SET)
  [8] STAT_CTS — Clear To Send
    0=STAT_CTS_CLEARED (CLEARED); 1=STAT_CTS_SET (SET)
  [7] STAT_TXFF — UART Transmit FIFO Full The meaning of this bit depends on the state of the FEN bit in the CTL0 register.
    0=STAT_TXFF_CLEARED (CLEARED); 1=STAT_TXFF_SET (SET)
  [6] STAT_TXFE — UART Transmit FIFO Empty The meaning of this bit depends on the state of the FEN bit in the CTL0 register.
    0=STAT_TXFE_CLEARED (CLEARED); 1=STAT_TXFE_SET (SET)
  [3] STAT_RXFF — UART Receive FIFO Full The meaning of this bit depends on the state of the FEN bit in the CTL0 register.
    0=STAT_RXFF_CLEARED (CLEARED); 1=STAT_RXFF_SET (SET)
  [2] STAT_RXFE — UART Receive FIFO Empty The meaning of this bit depends on the state of the FEN bit in the CTL0 register.
    0=STAT_RXFE_CLEARED (CLEARED); 1=STAT_RXFE_SET (SET)
  [0] STAT_BUSY — UART Busy This bit is set as soon as the transmit FIFO or TXBuffer becomes non-empty (regardless of whether UART is enabled) or if a receive data is currently ongoing (after the start edge have been detected until a complete byte, including all stop bits, has been received by the shift register). In IDLE_Line mode the Busy signal also stays set during the idle time generation.
    0=STAT_BUSY_CLEARED (CLEARED); 1=STAT_BUSY_SET (SET)
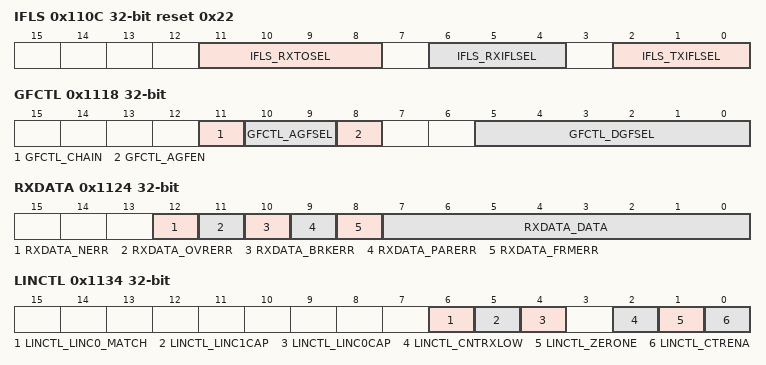
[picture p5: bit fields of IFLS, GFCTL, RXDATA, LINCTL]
0x110C IFLS reset 0x22 — UART Interrupt FIFO Level Select Register
  [11:8] IFLS_RXTOSEL — UART Receive Interrupt Timeout Select. When receiving no start edge for an additional character within the set bittimes a RX interrupt is set even if the FIFO level is not reached. A value of 0 disables this function.
  [6:4] IFLS_RXIFLSEL — UART Receive Interrupt FIFO Level Select The trigger points for the receive interrupt are as follows: Note: In ULP domain the trigger levels are used for: 0: LVL_1_4 4: LVL_FULL For undefined settings the default configuration is used.
  [2:0] IFLS_TXIFLSEL — UART Transmit Interrupt FIFO Level Select The trigger points for the transmit interrupt are as follows: Note: for undefined settings the default configuration is used.
0x1110 IBRD — UART Integer Baud-Rate Divisor Register
  [15:0] IBRD_DIVINT — Integer Baud-Rate Divisor
0x1114 FBRD — UART Fractional Baud-Rate Divisor Register
  [5:0] FBRD_DIVFRAC — Fractional Baud-Rate Divisor
0x1118 GFCTL (reset mask 0xFFFFFFFB) — Glitch Filter Control
  [11] GFCTL_CHAIN — Analog and digital noise filters chaining enable. 0 DISABLE: When 0, chaining is disabled and only digital filter output is available to IP logic for sampling 1 ENABLE: When 1, analog and digital glitch filters are chained and the output of the combination is made available to IP logic for sampling
    0=GFCTL_CHAIN_DISABLED (DISABLED); 1=GFCTL_CHAIN_ENABLED (ENABLED)
  [10:9] GFCTL_AGFSEL — Analog Glitch Suppression Pulse Width This field controls the pulse width select for the analog glitch suppression on the RX line. See device datasheet for exact values. (ULP UART only)
    0=GFCTL_AGFSEL_AGLIT_5 (AGLIT_5); 1=GFCTL_AGFSEL_AGLIT_10 (AGLIT_10); 2=GFCTL_AGFSEL_AGLIT_25 (AGLIT_25); 3=GFCTL_AGFSEL_AGLIT_50 (AGLIT_50)
  [8] GFCTL_AGFEN — Analog Glitch Suppression Enable
    0=GFCTL_AGFEN_DISABLE (DISABLE); 1=GFCTL_AGFEN_ENABLE (ENABLE)
  [5:0] GFCTL_DGFSEL — Glitch Suppression Pulse Width This field controls the pulse width select for glitch suppression on the RX line. The following values are the glitch suppression values in terms of functional clocks. In IRDA mode: Receive filter length. The minimum pulse length for receive is given by: t(MIN) = (DGFSEL) / f(IRTXCLK)
    0=GFCTL_DGFSEL_DISABLED (DISABLED)
0x1120 TXDATA — UART Transmit Data Register
  [7:0] TXDATA_DATA — Data Transmitted or Received Data that is to be transmitted via the UART is written to this field. When read, this field contains the data that was received by the UART.
0x1124 RXDATA ro — UART Receive Data Register
  [12] RXDATA_NERR — Noise Error. Writing to this bit has no effect. The flag is cleared by writing 1 to the NERR bit in the UART EVENT ICLR register.
    0=RXDATA_NERR_CLR (CLR); 1=RXDATA_NERR_SET (SET)
  [11] RXDATA_OVRERR — UART Receive Overrun Error Writing to this bit has no effect. The flag is cleared by writing 1 to the OVRERR bit in the UART EVENT ICLR register. In case of a receive FIFO overflow, the FIFO contents remain valid because no further data is written when the FIFO is full. Only the contents of the shift register are overwritten. The CPU must read the data in order to empty the FIFO.
    0=RXDATA_OVRERR_CLR (CLR); 1=RXDATA_OVRERR_SET (SET)
  [10] RXDATA_BRKERR — UART Break Error Writing to this bit has no effect. The flag is cleared by writing 1 to the BRKERR bit in the UART EVENT ICLR register. This error is associated with the character at the top of the FIFO. When a break occurs, only one 0 character is loaded into the FIFO. The next character is only enabled after the receive data input goes to a 1 (marking state) and the next valid start bit is received.
    0=RXDATA_BRKERR_CLR (CLR); 1=RXDATA_BRKERR_SET (SET)
  [9] RXDATA_PARERR — UART Parity Error Writing to this bit has no effect. The flag is cleared by writing 1 to the PARERR bit in the UART EVENT ICLR register.
    0=RXDATA_PARERR_CLR (CLR); 1=RXDATA_PARERR_SET (SET)
  [8] RXDATA_FRMERR — UART Framing Error Writing to this bit has no effect. The flag is cleared by writing 1 to the FRMERR bit in the UART EVENT ICLR register. This error is associated with the character at the top of the FIFO.
    0=RXDATA_FRMERR_CLR (CLR); 1=RXDATA_FRMERR_SET (SET)
  [7:0] RXDATA_DATA — Data Transmitted or Received Data that is to be transmitted via the UART is written to this field. When read, this field contains the data that was received by the UART.
0x1130 LINCNT — UART LIN Mode Counter Register
  [15:0] LINCNT_VALUE — 16 bit up counter clocked by the module clock of the UART.
0x1134 LINCTL — UART LIN Mode Control Register
  [6] LINCTL_LINC0_MATCH — Counter Compare Match Mode When this bit is set to 1 a counter compare match with LINC0 register triggers an LINC0 interrupt when enabled.
    0=LINCTL_LINC0_MATCH_DISABLE (DISABLE); 1=LINCTL_LINC0_MATCH_ENABLE (ENABLE)
  [5] LINCTL_LINC1CAP — Capture Counter on positive RXD Edge. When enabled the counter value is captured to LINC1 register on each positive RXD edge. A LINC1 interrupt is triggered when enabled.
    0=LINCTL_LINC1CAP_DISABLE (DISABLE); 1=LINCTL_LINC1CAP_ENABLE (ENABLE)
  [4] LINCTL_LINC0CAP — Capture Counter on negative RXD Edge. When enabled the counter value is captured to LINC0 register on each negative RXD edge. A LINC0 interrupt is triggered when enabled.
    0=LINCTL_LINC0CAP_DISABLE (DISABLE); 1=LINCTL_LINC0CAP_ENABLE (ENABLE)
  [2] LINCTL_CNTRXLOW — Count while low Signal on RXD When counter is enabled and the signal on RXD is low, the counter increments.
    0=LINCTL_CNTRXLOW_DISABLE (DISABLE); 1=LINCTL_CNTRXLOW_ENABLE (ENABLE)
  [1] LINCTL_ZERONE — Zero on negative Edge of RXD. When enabled the counter is set to 0 and starts counting on a negative edge of RXD
    0=LINCTL_ZERONE_DISABLE (DISABLE); 1=LINCTL_ZERONE_ENABLE (ENABLE)
  [0] LINCTL_CTRENA — LIN Counter Enable. LIN counter will only count when enabled.
    0=LINCTL_CTRENA_DISABLE (DISABLE); 1=LINCTL_CTRENA_ENABLE (ENABLE)
0x1138 LINC0 — UART LIN Mode Capture 0 Register
  [15:0] LINC0_DATA — 16 Bit Capture / Compare Register Captures current LINCTR value on RXD falling edge when enabled. It can generate a DATA interrupt on capture. If compare mode is enabled (DATA_MATCH = 1) a counter match can generate a LINC0 interrupt.
0x113C LINC1 — UART LIN Mode Capture 1 Register
  [15:0] LINC1_DATA — 16 Bit Capture / Compare Register Captures current LINCTR value on RXD rising edge when enabled. It can generate a LINC1 interrupt on capture.
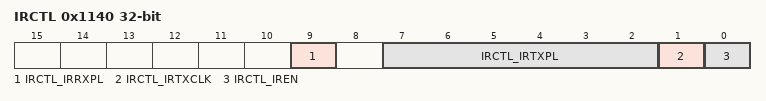
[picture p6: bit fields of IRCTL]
0x1140 IRCTL — eUSCI_Ax IrDA Control Word Register
  [9] IRCTL_IRRXPL — IrDA receive input UCAxRXD polarity
    0=IRCTL_IRRXPL_HIGH (HIGHPULSE); 1=IRCTL_IRRXPL_LOW (LOWPULSE)
  [7:2] IRCTL_IRTXPL — Transmit pulse length. Pulse length t(PULSE) = (IRTXPLx + 1) / [2 * f(IRTXCLK)] (IRTXCLK = functional clock of the UART)
  [1] IRCTL_IRTXCLK — IrDA transmit pulse clock select
    0=IRCTL_IRTXCLK_BITCLK (BITCLK); 1=IRCTL_IRTXCLK_BRCLK (BRCLK)
  [0] IRCTL_IREN — IrDA encoder/decoder enable
    0=IRCTL_IREN_DISABLE (DISABLE); 1=IRCTL_IREN_ENABLE (ENABLE)
0x1148 AMASK reset 0xFF — Self Address Mask Register
  [7:0] AMASK_VALUE — Self Address Mask for 9-Bit Mode This field contains the address mask that creates a set of addresses that should be matched. A 0 bit in the MSK bitfield configures, that the corresponding bit in the ADDR bitfield of the UART9BITADDR register is don't care. A 1 bit in the MSK bitfield configures, that the corresponding bit in the ADDR bitfield of the UART9BITADDR register must match.
0x114C ADDR — Self Address Register
  [7:0] ADDR_VALUE — Self Address for 9-Bit Mode This field contains the address that should be matched when UART9BITAMASK is FFh.
0x1160 CLKDIV2 — Clock Divider
  [2:0] CLKDIV2_RATIO — Selects divide ratio of module clock
    {v}=CLKDIV2_RATIO_DIV_BY_{v+1} (DIV_BY_{v+1}) (v=0..7)
